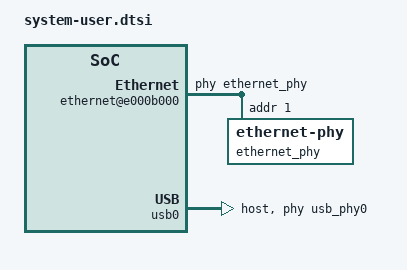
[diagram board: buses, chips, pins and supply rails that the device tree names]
/include/ "system-conf.dtsi"
/ {
	amba {

		ethernet@e000b000 {
			phy-handle = <&ethernet_phy>;
			ethernet_phy: ethernet-phy@1{
			reg = <1>;
                        device_type = "ethernet-phy";
                        /* dt-bindings/phy/realtek.h */
                        /* #define REALTEK_LED_LINK10           BIT(0)
                        #define REALTEK_LED_LINK100             BIT(1)
                        #define REALTEK_LED_LINK1000            BIT(3)
                        #define REALTEK_LED_ACT                 BIT(4)
                        #define REALTEK_LED_DEFAULT             BIT(7)
                        */
                        /* LED0=10+A, LED1=100+A, LED2=1000+A */
                        realtek,leds-config = <0x11 0x12 0x18>;
			};
		};
	};
        usb_phy0: phy0 {
                compatible = "ulpi-phy";
                #phy-cells = <0>;
                reg = <0xe0002000 0x1000>;
                view-port = <0x170>;
                drv-vbus;
        };
};

&usb0 {
	status = "okay";
	dr_mode = "host";
	usb-phy = <&usb_phy0>;
};

&flash0 {
        compatible = "jedec,spi-nor";
        reg = <0x0>;
        spi-tx-bus-width = <1>;
        spi-rx-bus-width = <4>;
        spi-max-frequency = <100000000>;
};
